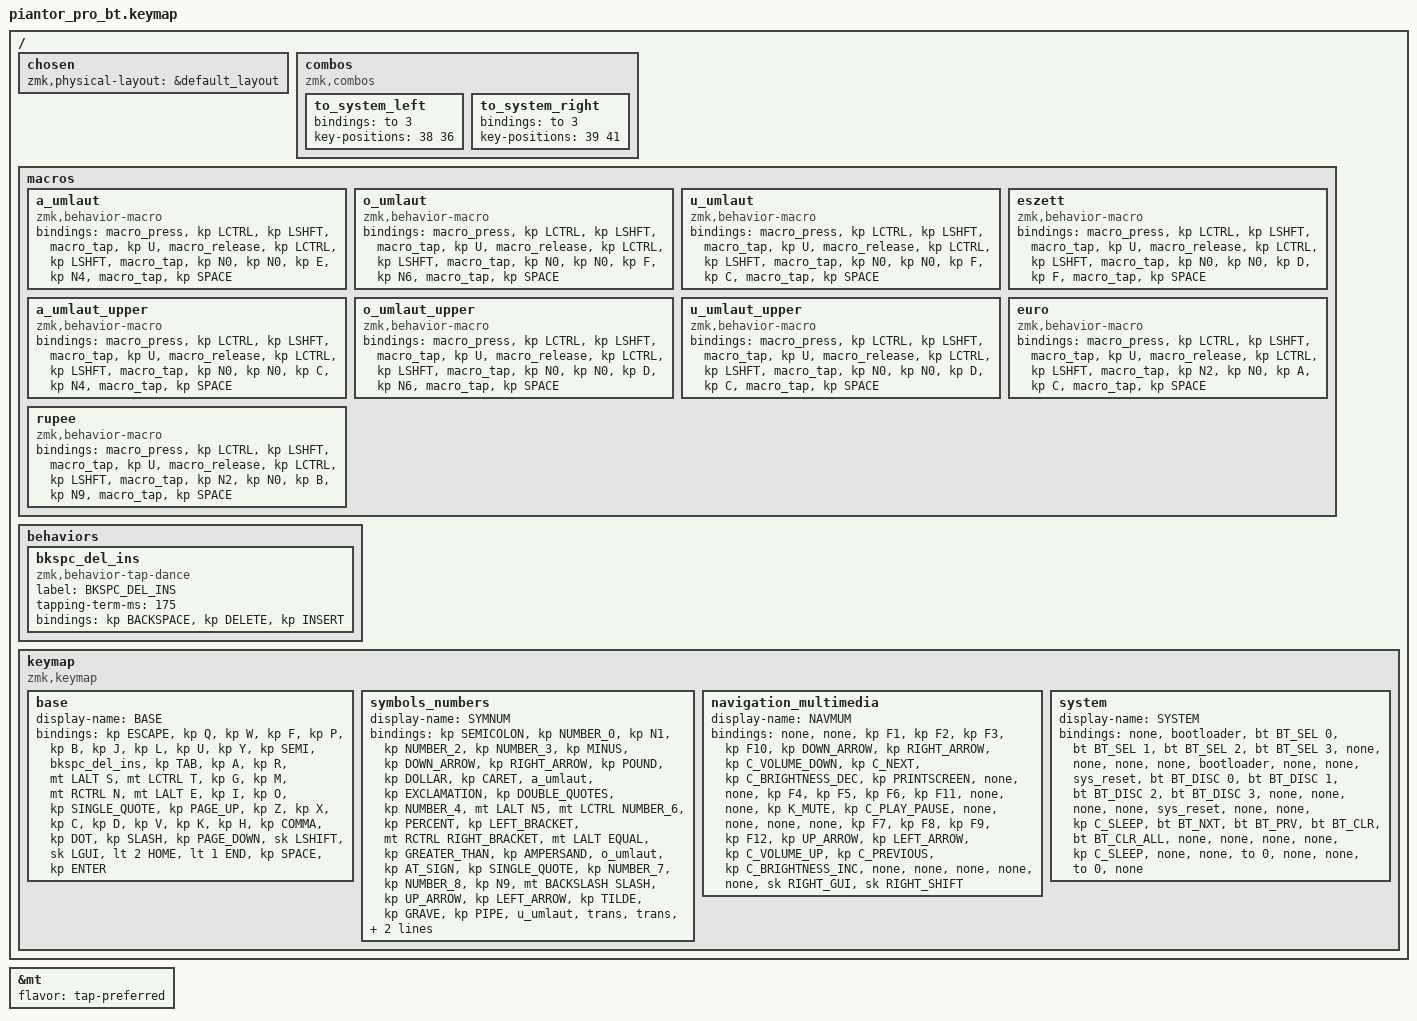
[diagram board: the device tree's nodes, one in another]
/*
 * Copyright (c) 2020 The ZMK Contributors
 *
 * SPDX-License-Identifier: MIT
 */

#include <behaviors.dtsi>
#include <dt-bindings/zmk/bt.h>
#include <dt-bindings/zmk/keys.h>

&mt { flavor = "tap-preferred"; };

/ {
    chosen { zmk,physical-layout = &default_layout; };
};

/ {
    combos {
        compatible = "zmk,combos";

        to_system_left {
            bindings = <&to 3>;
            key-positions = <38 36>;
        };

        to_system_right {
            bindings = <&to 3>;
            key-positions = <39 41>;
        };
    };

    macros {
        //
        // Unicode Macros for German Umlauts and Currency Symbols
        // Linux version using Ctrl+Shift+U method
        //
        // German Umlauts - Lowercase
        // ä - U+00E4

        a_umlaut: a_umlaut {
            compatible = "zmk,behavior-macro";
            #binding-cells = <0>;
            bindings =
                <&macro_press>,
                <&kp LCTRL &kp LSHFT>,
                <&macro_tap>,
                <&kp U>,
                <&macro_release>,
                <&kp LCTRL &kp LSHFT>,
                <&macro_tap>,
                <&kp N0 &kp N0 &kp E &kp N4>,
                <&macro_tap>,
                <&kp SPACE>;
        };

        // ö - U+00F6

        o_umlaut: o_umlaut {
            compatible = "zmk,behavior-macro";
            #binding-cells = <0>;
            bindings =
                <&macro_press>,
                <&kp LCTRL &kp LSHFT>,
                <&macro_tap>,
                <&kp U>,
                <&macro_release>,
                <&kp LCTRL &kp LSHFT>,
                <&macro_tap>,
                <&kp N0 &kp N0 &kp F &kp N6>,
                <&macro_tap>,
                <&kp SPACE>;
        };

        // ü - U+00FC

        u_umlaut: u_umlaut {
            compatible = "zmk,behavior-macro";
            #binding-cells = <0>;
            bindings =
                <&macro_press>,
                <&kp LCTRL &kp LSHFT>,
                <&macro_tap>,
                <&kp U>,
                <&macro_release>,
                <&kp LCTRL &kp LSHFT>,
                <&macro_tap>,
                <&kp N0 &kp N0 &kp F &kp C>,
                <&macro_tap>,
                <&kp SPACE>;
        };

        // ß - U+00DF

        eszett: eszett {
            compatible = "zmk,behavior-macro";
            #binding-cells = <0>;
            bindings =
                <&macro_press>,
                <&kp LCTRL &kp LSHFT>,
                <&macro_tap>,
                <&kp U>,
                <&macro_release>,
                <&kp LCTRL &kp LSHFT>,
                <&macro_tap>,
                <&kp N0 &kp N0 &kp D &kp F>,
                <&macro_tap>,
                <&kp SPACE>;
        };

        // German Umlauts - Uppercase
        // Ä - U+00C4

        a_umlaut_upper: a_umlaut_upper {
            compatible = "zmk,behavior-macro";
            #binding-cells = <0>;
            bindings =
                <&macro_press>,
                <&kp LCTRL &kp LSHFT>,
                <&macro_tap>,
                <&kp U>,
                <&macro_release>,
                <&kp LCTRL &kp LSHFT>,
                <&macro_tap>,
                <&kp N0 &kp N0 &kp C &kp N4>,
                <&macro_tap>,
                <&kp SPACE>;
        };

        // Ö - U+00D6

        o_umlaut_upper: o_umlaut_upper {
            compatible = "zmk,behavior-macro";
            #binding-cells = <0>;
            bindings =
                <&macro_press>,
                <&kp LCTRL &kp LSHFT>,
                <&macro_tap>,
                <&kp U>,
                <&macro_release>,
                <&kp LCTRL &kp LSHFT>,
                <&macro_tap>,
                <&kp N0 &kp N0 &kp D &kp N6>,
                <&macro_tap>,
                <&kp SPACE>;
        };

        // Ü - U+00DC

        u_umlaut_upper: u_umlaut_upper {
            compatible = "zmk,behavior-macro";
            #binding-cells = <0>;
            bindings =
                <&macro_press>,
                <&kp LCTRL &kp LSHFT>,
                <&macro_tap>,
                <&kp U>,
                <&macro_release>,
                <&kp LCTRL &kp LSHFT>,
                <&macro_tap>,
                <&kp N0 &kp N0 &kp D &kp C>,
                <&macro_tap>,
                <&kp SPACE>;
        };

        // Currency Symbols
        // € - U+20AC

        euro: euro {
            compatible = "zmk,behavior-macro";
            #binding-cells = <0>;
            bindings =
                <&macro_press>,
                <&kp LCTRL &kp LSHFT>,
                <&macro_tap>,
                <&kp U>,
                <&macro_release>,
                <&kp LCTRL &kp LSHFT>,
                <&macro_tap>,
                <&kp N2 &kp N0 &kp A &kp C>,
                <&macro_tap>,
                <&kp SPACE>;
        };

        // ₹ - U+20B9

        rupee: rupee {
            compatible = "zmk,behavior-macro";
            #binding-cells = <0>;
            bindings =
                <&macro_press>,
                <&kp LCTRL &kp LSHFT>,
                <&macro_tap>,
                <&kp U>,
                <&macro_release>,
                <&kp LCTRL &kp LSHFT>,
                <&macro_tap>,
                <&kp N2 &kp N0 &kp B &kp N9>,
                <&macro_tap>,
                <&kp SPACE>;
        };
    };

    behaviors {
        bkspc_del_ins: bkspc_del_ins {
            compatible = "zmk,behavior-tap-dance";
            label = "BKSPC_DEL_INS";
            #binding-cells = <0>;
            tapping-term-ms = <175>;
            bindings = <&kp BACKSPACE>, <&kp DELETE>, <&kp INSERT>;
        };
    };

    keymap {
        compatible = "zmk,keymap";

        base {
            display-name = "BASE";
            bindings = <
&kp ESCAPE  &kp Q  &kp W  &kp F  &kp P  &kp B  &kp J  &kp L  &kp U  &kp Y  &kp SEMI  &bkspc_del_ins  &kp TAB  &kp A  &kp R  &mt LALT S  &mt LCTRL T  &kp G  &kp M  &mt RCTRL N  &mt LALT E  &kp I  &kp O  &kp SINGLE_QUOTE  &kp PAGE_UP  &kp Z  &kp X  &kp C  &kp D  &kp V  &kp K  &kp H  &kp COMMA  &kp DOT  &kp SLASH  &kp PAGE_DOWN  &sk LSHIFT  &sk LGUI  &lt 2 HOME  &lt 1 END  &kp SPACE  &kp ENTER
            >;
        };

        symbols_numbers {
            display-name = "SYMNUM";
            bindings = <
&kp SEMICOLON  &kp NUMBER_0  &kp N1  &kp NUMBER_2  &kp NUMBER_3  &kp MINUS  &kp DOWN_ARROW  &kp RIGHT_ARROW  &kp POUND  &kp DOLLAR  &kp CARET  &a_umlaut  &kp EXCLAMATION  &kp DOUBLE_QUOTES  &kp NUMBER_4  &mt LALT N5  &mt LCTRL NUMBER_6  &kp PERCENT  &kp LEFT_BRACKET  &mt RCTRL RIGHT_BRACKET  &mt LALT EQUAL  &kp GREATER_THAN  &kp AMPERSAND  &o_umlaut  &kp AT_SIGN  &kp SINGLE_QUOTE  &kp NUMBER_7  &kp NUMBER_8  &kp N9  &mt BACKSLASH SLASH  &kp UP_ARROW  &kp LEFT_ARROW  &kp TILDE  &kp GRAVE  &kp PIPE  &u_umlaut  &trans  &trans  &mt RIGHT_PARENTHESIS LEFT_PARENTHESIS  &none  &euro  &rupee
            >;
        };

        navigation_multimedia {
            display-name = "NAVMUM";
            bindings = <
&none  &none  &kp F1  &kp F2  &kp F3  &kp F10  &kp DOWN_ARROW  &kp RIGHT_ARROW  &kp C_VOLUME_DOWN  &kp C_NEXT  &kp C_BRIGHTNESS_DEC  &kp PRINTSCREEN  &none  &none  &kp F4  &kp F5  &kp F6  &kp F11  &none  &none  &kp K_MUTE  &kp C_PLAY_PAUSE  &none  &none  &none  &none  &kp F7  &kp F8  &kp F9  &kp F12  &kp UP_ARROW  &kp LEFT_ARROW  &kp C_VOLUME_UP  &kp C_PREVIOUS  &kp C_BRIGHTNESS_INC  &none  &none  &none  &none  &none  &sk RIGHT_GUI  &sk RIGHT_SHIFT
            >;
        };

        system {
            display-name = "SYSTEM";
            bindings = <
&none  &bootloader  &bt BT_SEL 0  &bt BT_SEL 1  &bt BT_SEL 2  &bt BT_SEL 3  &none  &none  &none  &none  &bootloader  &none  &none  &sys_reset  &bt BT_DISC 0  &bt BT_DISC 1  &bt BT_DISC 2  &bt BT_DISC 3  &none  &none  &none  &none  &sys_reset  &none  &none  &kp C_SLEEP  &bt BT_NXT  &bt BT_PRV  &bt BT_CLR  &bt BT_CLR_ALL  &none  &none  &none  &none  &kp C_SLEEP  &none  &none  &to 0  &none  &none  &to 0  &none
            >;
        };
    };
};
